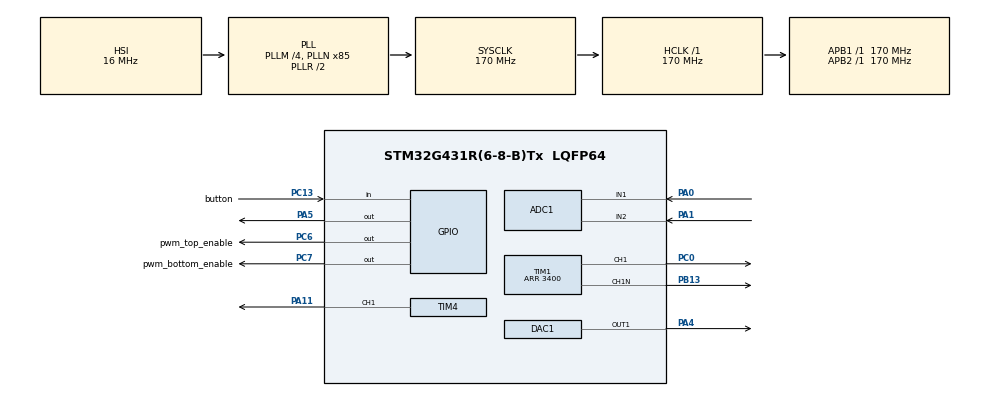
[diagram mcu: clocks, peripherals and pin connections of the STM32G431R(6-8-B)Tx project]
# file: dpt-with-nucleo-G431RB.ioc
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ADC1.Channel-0\#ChannelRegularConversion=ADC_CHANNEL_1
ADC1.Channel-1\#ChannelRegularConversion=ADC_CHANNEL_2
ADC1.ContinuousConvMode=ENABLE
ADC1.EOCSelection=ADC_EOC_SEQ_CONV
ADC1.ExternalTrigConv=ADC_EXTERNALTRIG_T1_TRGO
ADC1.NbrOfConversion=2
ADC1.NbrOfConversionFlag=1
ADC1.OffsetNumber-0\#ChannelRegularConversion=ADC_OFFSET_NONE
ADC1.OffsetNumber-1\#ChannelRegularConversion=ADC_OFFSET_NONE
ADC1.Rank-0\#ChannelRegularConversion=1
ADC1.Rank-1\#ChannelRegularConversion=2
ADC1.SamplingTime-0\#ChannelRegularConversion=ADC_SAMPLETIME_6CYCLES_5
ADC1.SamplingTime-1\#ChannelRegularConversion=ADC_SAMPLETIME_6CYCLES_5
ADC1.master=1
Dma.ADC1.0.Direction=DMA_PERIPH_TO_MEMORY
Dma.ADC1.0.EventEnable=DISABLE
Dma.ADC1.0.Instance=DMA1_Channel1
Dma.ADC1.0.MemDataAlignment=DMA_MDATAALIGN_HALFWORD
Dma.ADC1.0.MemInc=DMA_MINC_ENABLE
Dma.ADC1.0.Mode=DMA_CIRCULAR
Dma.ADC1.0.PeriphDataAlignment=DMA_PDATAALIGN_HALFWORD
Dma.ADC1.0.PeriphInc=DMA_PINC_DISABLE
Dma.ADC1.0.Polarity=HAL_DMAMUX_REQ_GEN_RISING
Dma.ADC1.0.Priority=DMA_PRIORITY_LOW
Dma.ADC1.0.RequestNumber=1
Dma.ADC1.0.SignalID=NONE
Dma.ADC1.0.SyncEnable=DISABLE
Dma.ADC1.0.SyncPolarity=HAL_DMAMUX_SYNC_NO_EVENT
Dma.ADC1.0.SyncRequestNumber=1
Dma.ADC1.0.SyncSignalID=NONE
Dma.Request0=ADC1
Mcu.Family=STM32G4
Mcu.Name=STM32G431R(6-8-B)Tx
Mcu.Package=LQFP64
NUCLEO-G431RB.BUTTON=1
NUCLEO-G431RB.LD1=true
NUCLEO-G431RB.VCP=true
NVIC.DMA1_Channel1_IRQn=true\:0\:0\:false\:false\:true\:false\:true\:true
NVIC.EXTI15_10_IRQn=true\:0\:0\:false\:false\:true\:false\:true\:true
NVIC.PriorityGroup=NVIC_PRIORITYGROUP_4
PA0.Mode=IN1-Single-Ended
PA0.Signal=ADC1_IN1
PA1.Mode=IN2-Single-Ended
PA1.Signal=ADC1_IN2
PA11.Signal=S_TIM4_CH1
PA13.GPIO_Label=T_SWDIO
PA13.Mode=Serial_Wire
PA13.Signal=SYS_JTMS-SWDIO
PA14.GPIO_Label=T_SWCLK
PA14.Mode=Serial_Wire
PA14.Signal=SYS_JTCK-SWCLK
PA2.Signal=LPUART1_TX
PA3.Signal=LPUART1_RX
PA4.Signal=COMP_DAC11_group
PA5.Signal=GPIO_Output
PB13.Mode=PWM Generation1 CH1 CH1N
PB13.Signal=TIM1_CH1N
PB3.GPIO_Label=T_SWO
PB3.Signal=SYS_JTDO-SWO
PC0.Signal=S_TIM1_CH1
PC13.GPIO_Label=button
PC13.GPIO_PuPd=GPIO_PULLDOWN
PC13.Signal=GPIO_Input
PC14-OSC32_IN.GPIO_Label=RCC_OSC32_OUT
PC14-OSC32_IN.Signal=RCC_OSC32_IN
PC15-OSC32_OUT.GPIO_Label=RCC_OSC32_OUT
PC15-OSC32_OUT.Signal=RCC_OSC32_OUT
PC6.GPIO_Label=pwm_top_enable
PC6.GPIO_PuPd=GPIO_PULLDOWN
PC6.Signal=GPIO_Output
PC7.GPIO_Label=pwm_bottom_enable
PC7.GPIO_PuPd=GPIO_PULLDOWN
PC7.Signal=GPIO_Output
PF0-OSC_IN.GPIO_Label=RCC_OSC_IN
PF0-OSC_IN.Signal=RCC_OSC_IN
PF1-OSC_OUT.GPIO_Label=RCC_OSC_OUT
PF1-OSC_OUT.Signal=RCC_OSC_OUT
ProjectManager.HeapSize=0x200
ProjectManager.StackSize=0x400
ProjectManager.TargetToolchain=STM32CubeIDE
RCC.ADC12Freq_Value=170000000
RCC.AHBFreq_Value=170000000
RCC.APB1Freq_Value=170000000
RCC.APB1TimFreq_Value=170000000
RCC.APB2Freq_Value=170000000
RCC.APB2TimFreq_Value=170000000
RCC.CortexFreq_Value=170000000
RCC.EXTERNAL_CLOCK_VALUE=12288000
RCC.HCLKFreq_Value=170000000
RCC.HSE_VALUE=24000000
RCC.HSI48_VALUE=48000000
RCC.HSI_VALUE=16000000
RCC.LSE_VALUE=32768
RCC.PLLM=RCC_PLLM_DIV4
RCC.PLLN=85
RCC.RTCClockSelection=RCC_RTCCLKSOURCE_LSE
RCC.SYSCLKFreq_VALUE=170000000
RCC.SYSCLKSource=RCC_SYSCLKSOURCE_PLLCLK
RCC.USBFreq_Value=170000000
RCC.VCOOutputFreq_Value=340000000
SH.COMP_DAC11_group.0=DAC1_OUT1,DAC_OUT1
SH.S_TIM1_CH1.0=TIM1_CH1,PWM Generation1 CH1 CH1N
SH.S_TIM4_CH1.0=TIM4_CH1,PWM Generation1 CH1
TIM1.AsymmetricalDeadTime=ENABLE
TIM1.Channel-PWM\ Generation1\ CH1\ CH1N=TIM_CHANNEL_1
TIM1.CounterMode=TIM_COUNTERMODE_UP
TIM1.DeadTime=40
TIM1.DeadTimePreload=ENABLE
TIM1.OC1Preload_PWM=DISABLE
TIM1.PeriodNoDither=3400
TIM1.TIM_MasterOutputTrigger=TIM_TRGO_UPDATE
TIM1.TIM_MasterOutputTrigger2=TIM_TRGO2_UPDATE
TIM4.AutoReloadPreload=TIM_AUTORELOAD_PRELOAD_ENABLE
TIM4.Channel-PWM\ Generation1\ CH1=TIM_CHANNEL_1
TIM4.PeriodNoDither=978
TIM4.Prescaler=169
TIM4.PulseNoDither_1=716
TIM4.TIM_MasterOutputTrigger=TIM_TRGO_UPDATE
VP_NUCLEO-G431RB_VS_BSP_COMMON.Mode=COMMON
VP_SYS_VS_DBSignals.Mode=DisableDeadBatterySignals
VP_TIM1_VS_ClockSourceINT.Mode=Internal
VP_TIM4_VS_ClockSourceINT.Mode=Internal
board=NUCLEO-G431RB

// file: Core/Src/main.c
/* USER CODE BEGIN Header */
/**
  ******************************************************************************
  * @file           : main.c
  * @brief          : Main program body
  ******************************************************************************
  * @attention
  *
  * Copyright (c) 2026 STMicroelectronics.
  * All rights reserved.
  *
  * This software is licensed under terms that can be found in the LICENSE file
  * in the root directory of this software component.
  * If no LICENSE file comes with this software, it is provided AS-IS.
  *
  ******************************************************************************
  */
/* USER CODE END Header */
#include "main.h"
#include "adc.h"
#include "dac.h"
#include "dma.h"
#include "tim.h"
#include "gpio.h"

/* USER CODE BEGIN Includes */
#include "dpt.h"
/* USER CODE END Includes */

COM_InitTypeDef BspCOMInit;

void SystemClock_Config(void);

int main(void)
{

  /* MCU Configuration--------------------------------------------------------*/

  /* Reset of all peripherals, Initializes the Flash interface and the Systick. */
  HAL_Init();

  /* Configure the system clock */
  SystemClock_Config();

  /* USER CODE BEGIN SysInit */
  DWT_Init();
  /* USER CODE END SysInit */

  /* Initialize all configured peripherals */
  MX_GPIO_Init();
  MX_DMA_Init();
  MX_ADC1_Init();
  MX_DAC1_Init();
  MX_TIM1_Init();
  MX_TIM4_Init();
  /* USER CODE BEGIN 2 */
  	  HAL_TIM_PWM_Start(&htim4, TIM_CHANNEL_1);
  	  /* 3a. SET atomico via BSRR (preferito, thread-safe) */
  	  GPIOC->BSRR = (1 << 6) | (1 << 7);   // PC6 e PC7 → HIGH
  /* USER CODE END 2 */

  /* Initialize leds */
  BSP_LED_Init(LED_GREEN);

  /* Initialize USER push-button, will be used to trigger an interrupt each time it's pressed.*/
  BSP_PB_Init(BUTTON_USER, BUTTON_MODE_EXTI);

  /* Initialize COM1 port (115200, 8 bits (7-bit data + 1 stop bit), no parity */
  BspCOMInit.BaudRate   = 115200;
  BspCOMInit.WordLength = COM_WORDLENGTH_8B;
  BspCOMInit.StopBits   = COM_STOPBITS_1;
  BspCOMInit.Parity     = COM_PARITY_NONE;
  BspCOMInit.HwFlowCtl  = COM_HWCONTROL_NONE;
  if (BSP_COM_Init(COM1, &BspCOMInit) != BSP_ERROR_NONE)
  {
    Error_Handler();
  }

  /* Infinite loop */
  /* USER CODE BEGIN WHILE */
  while (1)
  {
	    //STO
	  	  __HAL_TIM_SET_COMPARE(&htim4, TIM_CHANNEL_1, 750);

	    // Esempio: Esegui il test solo se premi il tasto blu (B1_Pin)
	      if (HAL_GPIO_ReadPin(button_GPIO_Port, button_Pin) == GPIO_PIN_SET) {
	    	  // Un piccolo debounce o attesa rilascio tasto
	          HAL_Delay(500);
	          // ESEGUE IL TEST UNA SOLA VOLTA
	          Run_DoublePulseTest();
	          // Protezione: aspetta che il tasto venga rilasciato prima di continuare
	          while(HAL_GPIO_ReadPin(button_GPIO_Port, button_Pin) == GPIO_PIN_SET) {
	          }
	      }

    /* USER CODE END WHILE */

  }
}

void SystemClock_Config(void)
{
  RCC_OscInitTypeDef RCC_OscInitStruct = {0};
  RCC_ClkInitTypeDef RCC_ClkInitStruct = {0};

  /** Configure the main internal regulator output voltage
  */
  HAL_PWREx_ControlVoltageScaling(PWR_REGULATOR_VOLTAGE_SCALE1_BOOST);

  /** Initializes the RCC Oscillators according to the specified parameters
  * in the RCC_OscInitTypeDef structure.
  */
  RCC_OscInitStruct.OscillatorType = RCC_OSCILLATORTYPE_HSI;
  RCC_OscInitStruct.HSIState = RCC_HSI_ON;
  RCC_OscInitStruct.HSICalibrationValue = RCC_HSICALIBRATION_DEFAULT;
  RCC_OscInitStruct.PLL.PLLState = RCC_PLL_ON;
  RCC_OscInitStruct.PLL.PLLSource = RCC_PLLSOURCE_HSI;
  RCC_OscInitStruct.PLL.PLLM = RCC_PLLM_DIV4;
  RCC_OscInitStruct.PLL.PLLN = 85;
  RCC_OscInitStruct.PLL.PLLP = RCC_PLLP_DIV2;
  RCC_OscInitStruct.PLL.PLLQ = RCC_PLLQ_DIV2;
  RCC_OscInitStruct.PLL.PLLR = RCC_PLLR_DIV2;
  if (HAL_RCC_OscConfig(&RCC_OscInitStruct) != HAL_OK)
  {
    Error_Handler();
  }

  /** Initializes the CPU, AHB and APB buses clocks
  */
  RCC_ClkInitStruct.ClockType = RCC_CLOCKTYPE_HCLK|RCC_CLOCKTYPE_SYSCLK
                              |RCC_CLOCKTYPE_PCLK1|RCC_CLOCKTYPE_PCLK2;
  RCC_ClkInitStruct.SYSCLKSource = RCC_SYSCLKSOURCE_PLLCLK;
  RCC_ClkInitStruct.AHBCLKDivider = RCC_SYSCLK_DIV1;
  RCC_ClkInitStruct.APB1CLKDivider = RCC_HCLK_DIV1;
  RCC_ClkInitStruct.APB2CLKDivider = RCC_HCLK_DIV1;

  if (HAL_RCC_ClockConfig(&RCC_ClkInitStruct, FLASH_LATENCY_4) != HAL_OK)
  {
    Error_Handler();
  }
}

void Error_Handler(void)
{
  __disable_irq();
  while (1)
  {
  }
}
